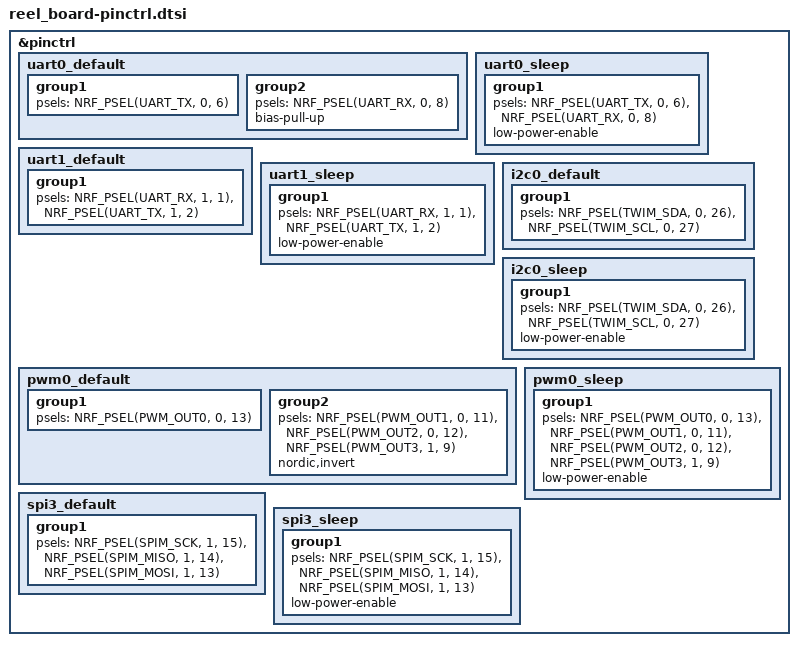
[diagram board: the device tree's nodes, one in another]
/*
 * Copyright (c) 2022 Nordic Semiconductor ASA
 *
 * SPDX-License-Identifier: Apache-2.0
 */

&pinctrl {
	uart0_default: uart0_default {
		group1 {
			psels = <NRF_PSEL(UART_TX, 0, 6)>;
		};

		group2 {
			psels = <NRF_PSEL(UART_RX, 0, 8)>;
			bias-pull-up;
		};
	};

	uart0_sleep: uart0_sleep {
		group1 {
			psels = <NRF_PSEL(UART_TX, 0, 6)>,
				<NRF_PSEL(UART_RX, 0, 8)>;
			low-power-enable;
		};
	};

	uart1_default: uart1_default {
		group1 {
			psels = <NRF_PSEL(UART_RX, 1, 1)>,
				<NRF_PSEL(UART_TX, 1, 2)>;
		};
	};

	uart1_sleep: uart1_sleep {
		group1 {
			psels = <NRF_PSEL(UART_RX, 1, 1)>,
				<NRF_PSEL(UART_TX, 1, 2)>;
			low-power-enable;
		};
	};

	i2c0_default: i2c0_default {
		group1 {
			psels = <NRF_PSEL(TWIM_SDA, 0, 26)>,
				<NRF_PSEL(TWIM_SCL, 0, 27)>;
		};
	};

	i2c0_sleep: i2c0_sleep {
		group1 {
			psels = <NRF_PSEL(TWIM_SDA, 0, 26)>,
				<NRF_PSEL(TWIM_SCL, 0, 27)>;
			low-power-enable;
		};
	};

	pwm0_default: pwm0_default {
		group1 {
			psels = <NRF_PSEL(PWM_OUT0, 0, 13)>;
		};

		group2 {
			psels = <NRF_PSEL(PWM_OUT1, 0, 11)>,
				<NRF_PSEL(PWM_OUT2, 0, 12)>,
				<NRF_PSEL(PWM_OUT3, 1, 9)>;
			nordic,invert;
		};
	};

	pwm0_sleep: pwm0_sleep {
		group1 {
			psels = <NRF_PSEL(PWM_OUT0, 0, 13)>,
				<NRF_PSEL(PWM_OUT1, 0, 11)>,
				<NRF_PSEL(PWM_OUT2, 0, 12)>,
				<NRF_PSEL(PWM_OUT3, 1, 9)>;
			low-power-enable;
		};
	};

	spi3_default: spi3_default {
		group1 {
			psels = <NRF_PSEL(SPIM_SCK, 1, 15)>,
				<NRF_PSEL(SPIM_MISO, 1, 14)>,
				<NRF_PSEL(SPIM_MOSI, 1, 13)>;
		};
	};

	spi3_sleep: spi3_sleep {
		group1 {
			psels = <NRF_PSEL(SPIM_SCK, 1, 15)>,
				<NRF_PSEL(SPIM_MISO, 1, 14)>,
				<NRF_PSEL(SPIM_MOSI, 1, 13)>;
			low-power-enable;
		};
	};
};
